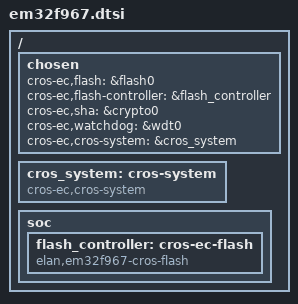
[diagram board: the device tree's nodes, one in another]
/* Copyright 2025 The ChromiumOS Authors.
 * Use of this source code is governed by a BSD-style license that can be
 * found in the LICENSE file.
 */

#include <cros/binman.dtsi>

/ {
	chosen {
		cros-ec,flash = &flash0;
		cros-ec,flash-controller = &flash_controller;
		cros-ec,sha = &crypto0;
		cros-ec,watchdog = &wdt0;
		cros-ec,cros-system = &cros_system;
	};

	cros_system: cros-system {
		compatible = "cros-ec,cros-system";
	};

	soc {
		flash_controller: cros-ec-flash {
			compatible = "elan,em32f967-cros-flash";
		};
	};
};
